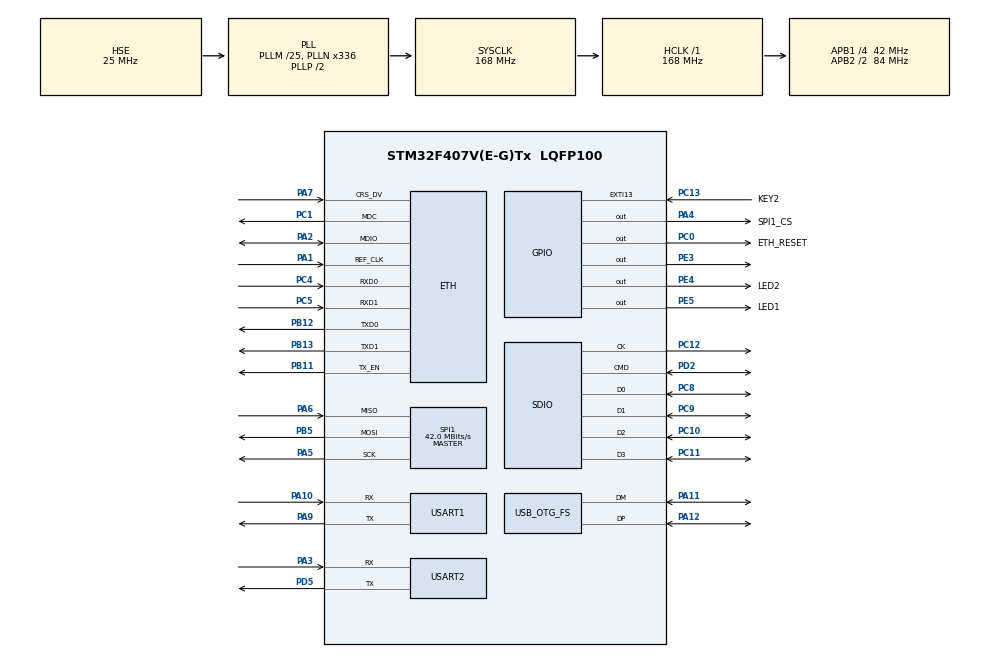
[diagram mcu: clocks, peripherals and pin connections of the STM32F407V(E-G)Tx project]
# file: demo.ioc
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ADC1.Channel-0\#ChannelRegularConversion=ADC_CHANNEL_TEMPSENSOR
ADC1.ContinuousConvMode=ENABLE
ADC1.NbrOfConversionFlag=1
ADC1.Rank-0\#ChannelRegularConversion=1
ADC1.SamplingTime-0\#ChannelRegularConversion=ADC_SAMPLETIME_3CYCLES
ADC1.ScanConvMode=ENABLE
ADC1.master=1
Dma.ADC1.0.Direction=DMA_PERIPH_TO_MEMORY
Dma.ADC1.0.FIFOMode=DMA_FIFOMODE_DISABLE
Dma.ADC1.0.Instance=DMA2_Stream0
Dma.ADC1.0.MemDataAlignment=DMA_MDATAALIGN_HALFWORD
Dma.ADC1.0.MemInc=DMA_MINC_ENABLE
Dma.ADC1.0.Mode=DMA_NORMAL
Dma.ADC1.0.PeriphDataAlignment=DMA_PDATAALIGN_HALFWORD
Dma.ADC1.0.PeriphInc=DMA_PINC_DISABLE
Dma.ADC1.0.Priority=DMA_PRIORITY_LOW
Dma.Request0=ADC1
Dma.Request1=SDIO_RX
Dma.Request2=SDIO_TX
Dma.SDIO_RX.1.Direction=DMA_PERIPH_TO_MEMORY
Dma.SDIO_RX.1.FIFOMode=DMA_FIFOMODE_ENABLE
Dma.SDIO_RX.1.FIFOThreshold=DMA_FIFO_THRESHOLD_FULL
Dma.SDIO_RX.1.Instance=DMA2_Stream3
Dma.SDIO_RX.1.MemBurst=DMA_MBURST_INC4
Dma.SDIO_RX.1.MemDataAlignment=DMA_MDATAALIGN_WORD
Dma.SDIO_RX.1.MemInc=DMA_MINC_ENABLE
Dma.SDIO_RX.1.Mode=DMA_PFCTRL
Dma.SDIO_RX.1.PeriphBurst=DMA_PBURST_INC4
Dma.SDIO_RX.1.PeriphDataAlignment=DMA_PDATAALIGN_WORD
Dma.SDIO_RX.1.PeriphInc=DMA_PINC_DISABLE
Dma.SDIO_RX.1.Priority=DMA_PRIORITY_LOW
Dma.SDIO_TX.2.Direction=DMA_MEMORY_TO_PERIPH
Dma.SDIO_TX.2.FIFOMode=DMA_FIFOMODE_ENABLE
Dma.SDIO_TX.2.FIFOThreshold=DMA_FIFO_THRESHOLD_FULL
Dma.SDIO_TX.2.Instance=DMA2_Stream6
Dma.SDIO_TX.2.MemBurst=DMA_MBURST_INC4
Dma.SDIO_TX.2.MemDataAlignment=DMA_MDATAALIGN_WORD
Dma.SDIO_TX.2.MemInc=DMA_MINC_ENABLE
Dma.SDIO_TX.2.Mode=DMA_PFCTRL
Dma.SDIO_TX.2.PeriphBurst=DMA_PBURST_INC4
Dma.SDIO_TX.2.PeriphDataAlignment=DMA_PDATAALIGN_WORD
Dma.SDIO_TX.2.PeriphInc=DMA_PINC_DISABLE
Dma.SDIO_TX.2.Priority=DMA_PRIORITY_LOW
ETH.MediaInterface=ETH_MEDIA_INTERFACE_RMII
ETH.PHY_Name_RMII=userPHY
ETH.PhyAddress=0
FATFS._CODE_PAGE=936
FATFS._MAX_SS=4096
FATFS._MIN_SS=512
FATFS._USE_LFN=0
IWDG.Prescaler=IWDG_PRESCALER_64
LWIP.GATEWAY_ADDRESS=192.168.031.001
LWIP.IP_ADDRESS=192.168.031.114
LWIP.LWIP_DHCP=0
LWIP.LWIP_NETIF_STATUS_CALLBACK=1
LWIP.NETMASK_ADDRESS=255.255.255.000
LWIP.Version=v2.1.2_Cube
Mcu.Family=STM32F4
Mcu.Name=STM32F407V(E-G)Tx
Mcu.Package=LQFP100
NVIC.DMA2_Stream0_IRQn=true\:0\:0\:true\:false\:true\:false\:true
NVIC.DMA2_Stream3_IRQn=true\:6\:0\:true\:false\:true\:false\:true
NVIC.DMA2_Stream6_IRQn=true\:6\:0\:true\:false\:true\:false\:true
NVIC.EXTI15_10_IRQn=true\:0\:0\:false\:false\:true\:true\:true
NVIC.OTG_FS_IRQn=true\:0\:0\:false\:false\:true\:false\:true
NVIC.PriorityGroup=NVIC_PRIORITYGROUP_4
NVIC.RTC_Alarm_IRQn=true\:0\:0\:false\:false\:true\:true\:true
NVIC.RTC_WKUP_IRQn=true\:0\:0\:false\:false\:true\:true\:true
NVIC.SDIO_IRQn=true\:5\:0\:true\:false\:true\:true\:true
NVIC.USART1_IRQn=true\:0\:0\:false\:false\:true\:true\:true
NVIC.USART2_IRQn=true\:0\:0\:false\:false\:true\:true\:true
PA1.Mode=RMII
PA1.Signal=ETH_REF_CLK
PA10.Mode=Asynchronous
PA10.Signal=USART1_RX
PA11.Mode=Device_Only
PA11.Signal=USB_OTG_FS_DM
PA12.Mode=Device_Only
PA12.Signal=USB_OTG_FS_DP
PA2.Mode=RMII
PA2.Signal=ETH_MDIO
PA3.Mode=Asynchronous
PA3.Signal=USART2_RX
PA4.GPIO_Label=SPI1_CS
PA4.Signal=GPIO_Output
PA5.Mode=Full_Duplex_Master
PA5.Signal=SPI1_SCK
PA6.Mode=Full_Duplex_Master
PA6.Signal=SPI1_MISO
PA7.Mode=RMII
PA7.Signal=ETH_CRS_DV
PA9.Mode=Asynchronous
PA9.Signal=USART1_TX
PB11.Mode=RMII
PB11.Signal=ETH_TX_EN
PB12.Mode=RMII
PB12.Signal=ETH_TXD0
PB13.Mode=RMII
PB13.Signal=ETH_TXD1
PB5.Mode=Full_Duplex_Master
PB5.Signal=SPI1_MOSI
PC0.GPIO_Label=ETH_RESET
PC0.Signal=GPIO_Output
PC1.Mode=RMII
PC1.Signal=ETH_MDC
PC10.Mode=SD_4_bits_Wide_bus
PC10.Signal=SDIO_D2
PC11.Mode=SD_4_bits_Wide_bus
PC11.Signal=SDIO_D3
PC12.Mode=SD_4_bits_Wide_bus
PC12.Signal=SDIO_CK
PC13-ANTI_TAMP.GPIO_Label=KEY2
PC13-ANTI_TAMP.GPIO_ModeDefaultEXTI=GPIO_MODE_IT_FALLING
PC13-ANTI_TAMP.GPIO_PuPd=GPIO_PULLUP
PC13-ANTI_TAMP.Signal=GPXTI13
PC14-OSC32_IN.Mode=LSE-External-Oscillator
PC14-OSC32_IN.Signal=RCC_OSC32_IN
PC15-OSC32_OUT.Mode=LSE-External-Oscillator
PC15-OSC32_OUT.Signal=RCC_OSC32_OUT
PC4.Mode=RMII
PC4.Signal=ETH_RXD0
PC5.Mode=RMII
PC5.Signal=ETH_RXD1
PC8.Mode=SD_4_bits_Wide_bus
PC8.Signal=SDIO_D0
PC9.Mode=SD_4_bits_Wide_bus
PC9.Signal=SDIO_D1
PD2.Mode=SD_4_bits_Wide_bus
PD2.Signal=SDIO_CMD
PD5.Mode=Asynchronous
PD5.Signal=USART2_TX
PE3.Signal=GPIO_Output
PE4.GPIO_Label=LED2
PE4.PinState=GPIO_PIN_SET
PE4.Signal=GPIO_Output
PE5.GPIO_Label=LED1
PE5.PinState=GPIO_PIN_SET
PE5.Signal=GPIO_Output
PH0-OSC_IN.Mode=HSE-External-Oscillator
PH0-OSC_IN.Signal=RCC_OSC_IN
PH1-OSC_OUT.Mode=HSE-External-Oscillator
PH1-OSC_OUT.Signal=RCC_OSC_OUT
ProjectManager.HeapSize=0x2000
ProjectManager.StackSize=0x2000
ProjectManager.TargetToolchain=MDK-ARM V5.27
RCC.48MHZClocksFreq_Value=48000000
RCC.AHBFreq_Value=168000000
RCC.APB1CLKDivider=RCC_HCLK_DIV4
RCC.APB1Freq_Value=42000000
RCC.APB1TimFreq_Value=84000000
RCC.APB2CLKDivider=RCC_HCLK_DIV2
RCC.APB2Freq_Value=84000000
RCC.APB2TimFreq_Value=168000000
RCC.CortexFreq_Value=168000000
RCC.HCLKFreq_Value=168000000
RCC.HSE_VALUE=25000000
RCC.HSI_VALUE=16000000
RCC.PLLM=25
RCC.PLLN=336
RCC.PLLQ=7
RCC.RCC_RTC_Clock_Source=RCC_RTCCLKSOURCE_LSE
RCC.RCC_RTC_Clock_SourceVirtual=RCC_RTCCLKSOURCE_LSE
RCC.SYSCLKFreq_VALUE=168000000
RCC.SYSCLKSource=RCC_SYSCLKSOURCE_PLLCLK
RCC.VCOOutputFreq_Value=336000000
RTC.Alarm=RTC_ALARM_A
RTC.AlarmMaskDateWeekDay=RTC_ALARMMASK_DATEWEEKDAY
RTC.Alarm_B=RTC_ALARM_B
RTC.Date=19
RTC.Format=RTC_FORMAT_BIN
RTC.Hours=12
RTC.Minutes=55
RTC.Month=RTC_MONTH_NOVEMBER
RTC.WakeUpClock=RTC_WAKEUPCLOCK_CK_SPRE_16BITS
RTC.WakeUpCounter=5
RTC.Year=20
SDIO.ClockDiv=2
SPI1.CLKPhase=SPI_PHASE_2EDGE
SPI1.CLKPolarity=SPI_POLARITY_HIGH
SPI1.CalculateBaudRate=42.0 MBits/s
SPI1.Direction=SPI_DIRECTION_2LINES
SPI1.Mode=SPI_MODE_MASTER
SPI1.VirtualType=VM_MASTER
USART1.VirtualMode=VM_ASYNC
USART2.VirtualMode=VM_ASYNC
USB_DEVICE.CLASS_NAME_FS=MSC
USB_DEVICE.MSC_MEDIA_PACKET-MSC_FS=4096
USB_DEVICE.USBD_MAX_NUM_CONFIGURATION-MSC_FS=1
USB_DEVICE.USBD_MAX_NUM_INTERFACES-MSC_FS=1
USB_DEVICE.USBD_MAX_STR_DESC_SIZ-MSC_FS=512
USB_DEVICE.VirtualMode-MSC_FS=Msc
USB_DEVICE.VirtualModeFS=Msc_FS
USB_OTG_FS.VirtualMode=Device_Only
VP_ADC1_TempSens_Input.Mode=IN-TempSens
VP_FATFS_VS_Generic.Mode=User_defined
VP_FATFS_VS_SDIO.Mode=SDIO
VP_IWDG_VS_IWDG.Mode=IWDG_Activate
VP_LWIP_VS_Enabled.Mode=Enabled
VP_RTC_VS_RTC_Activate.Mode=RTC_Enabled
VP_RTC_VS_RTC_Alarm_A_Intern.Mode=Alarm A
VP_RTC_VS_RTC_Alarm_B_Intern.Mode=Alarm B
VP_RTC_VS_RTC_Calendar.Mode=RTC_Calendar
VP_RTC_VS_RTC_WakeUp_intern.Mode=WakeUp
VP_USB_DEVICE_VS_USB_DEVICE_MSC_FS.Mode=MSC_FS
board=custom

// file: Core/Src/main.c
/* USER CODE BEGIN Header */
/**
  ******************************************************************************
  * @file           : main.c
  * @brief          : Main program body
  ******************************************************************************
  * @attention
  *
  * <h2><center>&copy; Copyright (c) 2020 STMicroelectronics.
  * All rights reserved.</center></h2>
  *
  * This software component is licensed by ST under BSD 3-Clause license,
  * the "License"; You may not use this file except in compliance with the
  * License. You may obtain a copy of the License at:
  *                        opensource.org/licenses/BSD-3-Clause
  *
  ******************************************************************************
  */
/* USER CODE END Header */
#include "main.h"
#include "adc.h"
#include "dma.h"
#include "fatfs.h"
#include "iwdg.h"
#include "lwip.h"
#include "rtc.h"
#include "sdio.h"
#include "spi.h"
#include "usart.h"
#include "usb_device.h"
#include "gpio.h"

/* USER CODE BEGIN Includes */
#include "app_manager.h"
#include "stdio.h"
#include "stm32f4xx_hal_sd.h"
#include "driver_spi_flash.h"

/* USER CODE END Includes */

void SystemClock_Config(void);
/* USER CODE BEGIN PFP */
HAL_SD_CardCIDTypeDef SD_CardCID;
/* USER CODE END PFP */

int main(void)
{

  /* MCU Configuration--------------------------------------------------------*/

  /* Reset of all peripherals, Initializes the Flash interface and the Systick. */
  HAL_Init();

  /* Configure the system clock */
  SystemClock_Config();

  /* Initialize all configured peripherals */
  MX_GPIO_Init();
  MX_DMA_Init();
  MX_USART1_UART_Init();
  MX_USART2_UART_Init();
  MX_ADC1_Init();
  MX_IWDG_Init();
  MX_RTC_Init();
  MX_SDIO_SD_Init();
  MX_FATFS_Init();
  MX_SPI1_Init();
  MX_LWIP_Init();
  MX_USB_DEVICE_Init();
  /* USER CODE BEGIN 2 */
	LL_USART_EnableIT_RXNE(USART1);
	LL_USART_EnableIT_PE(USART1);

	driver_spi_flash_init();
	BSP_SD_Init();

	app_manager_init();
  /* USER CODE END 2 */

  /* Infinite loop */
  /* USER CODE BEGIN WHILE */
  while (1)
  {

		app_manager_handle();
		//MX_LWIP_Process();

    /* USER CODE END WHILE */

  }
}

void SystemClock_Config(void)
{
  RCC_OscInitTypeDef RCC_OscInitStruct = {0};
  RCC_ClkInitTypeDef RCC_ClkInitStruct = {0};
  RCC_PeriphCLKInitTypeDef PeriphClkInitStruct = {0};

  /** Configure the main internal regulator output voltage
  */
  __HAL_RCC_PWR_CLK_ENABLE();
  __HAL_PWR_VOLTAGESCALING_CONFIG(PWR_REGULATOR_VOLTAGE_SCALE1);
  /** Initializes the RCC Oscillators according to the specified parameters
  * in the RCC_OscInitTypeDef structure.
  */
  RCC_OscInitStruct.OscillatorType = RCC_OSCILLATORTYPE_LSI|RCC_OSCILLATORTYPE_HSE
                              |RCC_OSCILLATORTYPE_LSE;
  RCC_OscInitStruct.HSEState = RCC_HSE_ON;
  RCC_OscInitStruct.LSEState = RCC_LSE_ON;
  RCC_OscInitStruct.LSIState = RCC_LSI_ON;
  RCC_OscInitStruct.PLL.PLLState = RCC_PLL_ON;
  RCC_OscInitStruct.PLL.PLLSource = RCC_PLLSOURCE_HSE;
  RCC_OscInitStruct.PLL.PLLM = 25;
  RCC_OscInitStruct.PLL.PLLN = 336;
  RCC_OscInitStruct.PLL.PLLP = RCC_PLLP_DIV2;
  RCC_OscInitStruct.PLL.PLLQ = 7;
  if (HAL_RCC_OscConfig(&RCC_OscInitStruct) != HAL_OK)
  {
    Error_Handler();
  }
  /** Initializes the CPU, AHB and APB buses clocks
  */
  RCC_ClkInitStruct.ClockType = RCC_CLOCKTYPE_HCLK|RCC_CLOCKTYPE_SYSCLK
                              |RCC_CLOCKTYPE_PCLK1|RCC_CLOCKTYPE_PCLK2;
  RCC_ClkInitStruct.SYSCLKSource = RCC_SYSCLKSOURCE_PLLCLK;
  RCC_ClkInitStruct.AHBCLKDivider = RCC_SYSCLK_DIV1;
  RCC_ClkInitStruct.APB1CLKDivider = RCC_HCLK_DIV4;
  RCC_ClkInitStruct.APB2CLKDivider = RCC_HCLK_DIV2;

  if (HAL_RCC_ClockConfig(&RCC_ClkInitStruct, FLASH_LATENCY_5) != HAL_OK)
  {
    Error_Handler();
  }
  PeriphClkInitStruct.PeriphClockSelection = RCC_PERIPHCLK_RTC;
  PeriphClkInitStruct.RTCClockSelection = RCC_RTCCLKSOURCE_LSE;
  if (HAL_RCCEx_PeriphCLKConfig(&PeriphClkInitStruct) != HAL_OK)
  {
    Error_Handler();
  }
}

void Error_Handler(void)
{
}

/************************ (C) COPYRIGHT STMicroelectronics *****END OF FILE****/
